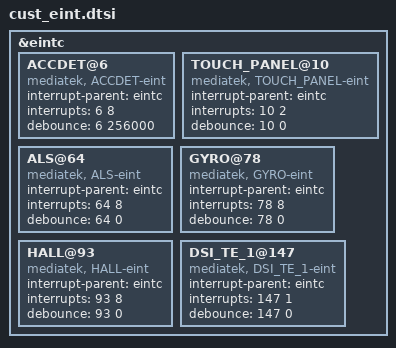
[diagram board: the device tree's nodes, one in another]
/*
 * Generated by MTK SP DrvGen Version 03.13.6 for MT6753. Copyright MediaTek Inc. (C) 2013.
 * Thu Aug 13 20:13:59 2015
 * Do Not Modify the File.
 */

/*************************
 * EINT DTSI File
*************************/

&eintc {
	ACCDET@6 {
		compatible = "mediatek, ACCDET-eint";
		interrupt-parent = <&eintc>;
		interrupts = <6 8>;
		debounce = <6 256000>;
	};

	TOUCH_PANEL@10 {
		compatible = "mediatek, TOUCH_PANEL-eint";
		interrupt-parent = <&eintc>;
		interrupts = <10 2>;
		debounce = <10 0>;
	};

	ALS@64 {
		compatible = "mediatek, ALS-eint";
		interrupt-parent = <&eintc>;
		interrupts = <64 8>;
		debounce = <64 0>;
	};

	GYRO@78 {
		compatible = "mediatek, GYRO-eint";
		interrupt-parent = <&eintc>;
		interrupts = <78 8>;
		debounce = <78 0>;
	};

	HALL@93 {
		compatible = "mediatek, HALL-eint";
		interrupt-parent = <&eintc>;
		interrupts = <93 8>;
		debounce = <93 0>;
	};

	DSI_TE_1@147 {
		compatible = "mediatek, DSI_TE_1-eint";
		interrupt-parent = <&eintc>;
		interrupts = <147 1>;
		debounce = <147 0>;
	};

};
